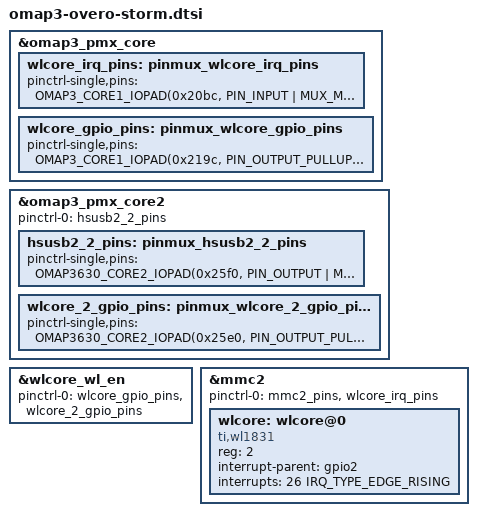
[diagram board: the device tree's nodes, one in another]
/*
 * Copyright (C) 2014 Florian Vaussard, EPFL Mobots group
 *
 * This program is free software; you can redistribute it and/or modify
 * it under the terms of the GNU General Public License version 2 as
 * published by the Free Software Foundation.
 */

#include "omap36xx.dtsi"
#include "omap3-overo-base.dtsi"

&omap3_pmx_core {
	wlcore_irq_pins: pinmux_wlcore_irq_pins {
		pinctrl-single,pins = <
			OMAP3_CORE1_IOPAD(0x20bc, PIN_INPUT | MUX_MODE4)		/* gpmc_ncs7.gpio_58 */
		>;
	};

	wlcore_gpio_pins: pinmux_wlcore_gpio_pins {
		pinctrl-single,pins = <
			/* BT enable */
			OMAP3_CORE1_IOPAD(0x219c, PIN_OUTPUT_PULLUP | MUX_MODE4) 	/* uart3_rts_sd.gpio_164 */
		>;
	};
};

&omap3_pmx_core2 {
	pinctrl-names = "default";
	pinctrl-0 = <
			&hsusb2_2_pins
	>;

	hsusb2_2_pins: pinmux_hsusb2_2_pins {
		pinctrl-single,pins = <
			OMAP3630_CORE2_IOPAD(0x25f0, PIN_OUTPUT | MUX_MODE3)		/* etk_d10.hsusb2_clk */
			OMAP3630_CORE2_IOPAD(0x25f2, PIN_OUTPUT | MUX_MODE3)		/* etk_d11.hsusb2_stp */
			OMAP3630_CORE2_IOPAD(0x25f4, PIN_INPUT_PULLDOWN | MUX_MODE3)	/* etk_d12.hsusb2_dir */
			OMAP3630_CORE2_IOPAD(0x25f6, PIN_INPUT_PULLDOWN | MUX_MODE3)	/* etk_d13.hsusb2_nxt */
			OMAP3630_CORE2_IOPAD(0x25f8, PIN_INPUT_PULLDOWN | MUX_MODE3)	/* etk_d14.hsusb2_data0 */
			OMAP3630_CORE2_IOPAD(0x25fa, PIN_INPUT_PULLDOWN | MUX_MODE3)	/* etk_d15.hsusb2_data1 */
		>;
	};

	wlcore_2_gpio_pins: pinmux_wlcore_2_gpio_pins {
		pinctrl-single,pins = <
			/* WL enable */
			OMAP3630_CORE2_IOPAD(0x25e0, PIN_OUTPUT_PULLUP | MUX_MODE4)	/* etk_d2.gpio_16 */
		>;
	};
};

&wlcore_wl_en {
	pinctrl-names = "default";
	pinctrl-0 = <&wlcore_gpio_pins &wlcore_2_gpio_pins>;
};

&mmc2 {
	pinctrl-names = "default";
	pinctrl-0 = <&mmc2_pins &wlcore_irq_pins>;

	#address-cells = <1>;
	#size-cells = <0>;
	wlcore: wlcore@0 {
		compatible = "ti,wl1831";
		reg = <2>;
		interrupt-parent = <&gpio2>;
		interrupts = <26 IRQ_TYPE_EDGE_RISING>; /* gpio_58 */
	};

};
